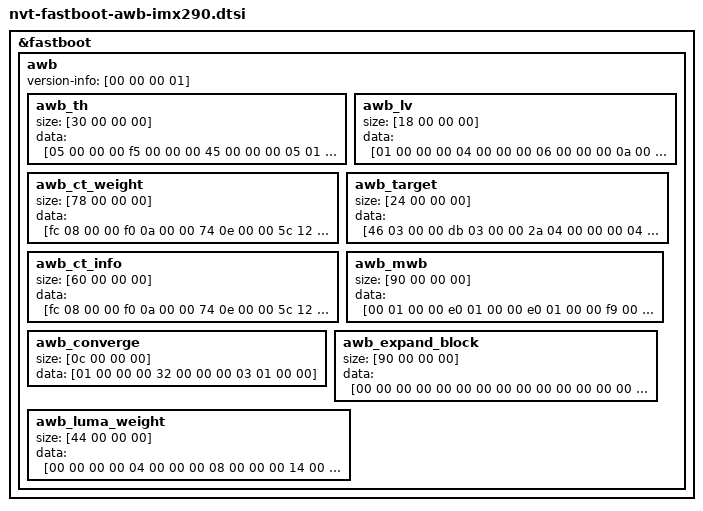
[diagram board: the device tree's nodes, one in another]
/*
 * Novatek Ltd. NVT9856x ISP part of dts
 */

&fastboot {
	awb {
		version-info = [00 00 00 01];
		awb_th {
			size = [30 00 00 00];
			data = [05 00 00 00 f5 00 00 00 45 00 00 00 05 01 00 00 ce ff ff ff 83 00 00 00 2e 00 00 00 a7 00 00 00 17 00 00 00 5e 00 00 00 1b 00 00 00 32 00 00 00];
		};
		awb_lv {
			size = [18 00 00 00];
			data = [01 00 00 00 04 00 00 00 06 00 00 00 0a 00 00 00 0e 00 00 00 1a 00 00 00];
		};
		awb_ct_weight {
			size = [78 00 00 00];
			data = [fc 08 00 00 f0 0a 00 00 74 0e 00 00 5c 12 00 00 64 19 00 00 f8 2a 00 00 10 03 00 00 46 03 00 00 97 03 00 00 db 03 00 00 2a 04 00 00 6c 04 00 00 01 00 00 00 01 00 00 00 01 00 00 00 01 00 00 00 01 00 00 00 01 00 00 00 01 00 00 00 01 00 00 00 01 00 00 00 01 00 00 00 01 00 00 00 01 00 00 00 01 00 00 00 01 00 00 00 01 00 00 00 01 00 00 00 01 00 00 00 01 00 00 00];
		};
		awb_target {
			size = [24 00 00 00];
			data = [46 03 00 00 db 03 00 00 2a 04 00 00 00 04 00 00 00 04 00 00 00 04 00 00 00 04 00 00 00 04 00 00 00 04 00 00];
		};
		awb_ct_info {
			size = [60 00 00 00];
			data = [fc 08 00 00 f0 0a 00 00 74 0e 00 00 5c 12 00 00 64 19 00 00 f8 2a 00 00 f5 00 00 00 19 01 00 00 6d 01 00 00 b0 01 00 00 ea 01 00 00 6f 02 00 00 00 01 00 00 00 01 00 00 00 01 00 00 00 01 00 00 00 01 00 00 00 01 00 00 c4 03 00 00 1c 03 00 00 9b 02 00 00 16 02 00 00 88 01 00 00 58 01 00 00];
		};
		awb_mwb {
			size = [90 00 00 00];
			data = [00 01 00 00 e0 01 00 00 e0 01 00 00 f9 00 00 00 1d 01 00 00 00 01 00 00 00 01 00 00 00 01 00 00 00 01 00 00 00 01 00 00 00 01 00 00 00 01 00 00 00 01 00 00 00 01 00 00 00 01 00 00 00 01 00 00 00 01 00 00 00 01 00 00 00 01 00 00 00 01 00 00 00 01 00 00 00 01 00 00 00 01 00 00 00 01 00 00 00 01 00 00 79 01 00 00 40 01 00 00 47 03 00 00 26 03 00 00 00 01 00 00 00 01 00 00 00 01 00 00 00 01 00 00 00 01 00 00 00 01 00 00 00 01 00 00];
		};
		awb_converge {
			size = [0c 00 00 00];
			data = [01 00 00 00 32 00 00 00 03 01 00 00];
		};
		awb_expand_block {
			size = [90 00 00 00];
			data = [00 00 00 00 00 00 00 00 00 00 00 00 00 00 00 00 06 00 00 00 06 00 00 00 06 00 00 00 06 00 00 00 0a 00 00 00 0a 00 00 00 0a 00 00 00 0a 00 00 00 05 00 00 00 05 00 00 00 05 00 00 00 05 00 00 00 f5 00 00 00 f5 00 00 00 f5 00 00 00 f5 00 00 00 73 00 00 00 69 00 00 00 5b 00 00 00 72 00 00 00 8d 00 00 00 7a 00 00 00 69 00 00 00 80 00 00 00 0e 00 00 00 38 00 00 00 12 00 00 00 20 00 00 00 28 00 00 00 4a 00 00 00 20 00 00 00 cb ff ff ff];
		};
		awb_luma_weight {
			size = [44 00 00 00];
			data = [00 00 00 00 04 00 00 00 08 00 00 00 14 00 00 00 20 00 00 00 c0 00 00 00 d0 00 00 00 e0 00 00 00 f0 00 00 00 01 00 00 00 01 00 00 00 01 00 00 00 01 00 00 00 01 00 00 00 01 00 00 00 01 00 00 00 01 00 00 00];
		};
	};
};
